# STM32U5G9xx register map
File version: 1.0
Registers are 32-bit, read-write, reset 0x0 unless marked. A register's access mark holds for its fields unless they carry their own. Offsets are from the block's base; [hi:lo] are bit positions; {n}, {i} and the like mark numbered series; 'fields as' and 'values as' point back to an identical list.

## RCC — Reset and Clock Control
Base 0x46020C00
Same registers: RCC_S 0x56020C00
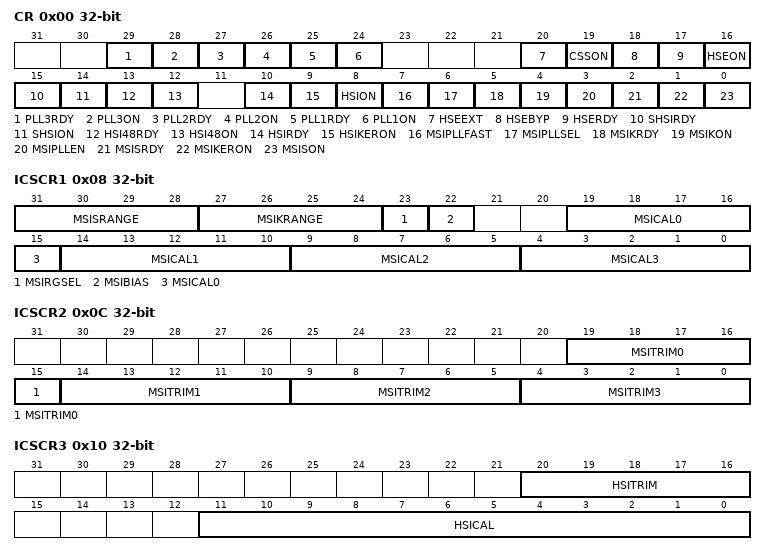
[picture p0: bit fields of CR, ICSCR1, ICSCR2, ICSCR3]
0x00 CR — RCC clock control register
  [29] PLL3RDY — System PLL 3 Ready Flag
  [28] PLL3ON — System PLL 3 Enable
  [27] PLL2RDY — System PLL 2 Ready Flag
  [26] PLL2ON — System PLL 2 Enable
  [25] PLL1RDY — System PLL 1 Clock Ready Flag
  [24] PLL1ON — System PLL 1 Clock Enable
  [20] HSEEXT — External High Speed clock type in Bypass Mode
    0=ANALOG_MODE (HSE clock used as ANALOG clock source); 1=DIGITAL_MODE (HSE clock used as DIGITAL clock source)
  [19] CSSON — HSE Clock Security System Enable
  [18] HSEBYP — External High Speed Oscillator (HSE) Clock Bypass
  [17] HSERDY — External High Speed Oscillator (HSE) Clock Ready
  [16] HSEON — External High Speed Oscillator (HSE) Clock Enable
  [15] SHSIRDY — Internal High Speed Secure (SHSI) Clock Ready Flag
  [14] SHSION — Internal High Speed Secure (SHSI) Clock Enable
  [13] HSI48RDY — Internal High Speed Oscillator (HSI48) Clock Ready Flag
  [12] HSI48ON — Internal High Speed Oscillator (HSI48) Clock Enable
  [10] HSIRDY — Internal High Speed Oscillator (HSI16) Clock Ready Flag
  [9] HSIKERON — Internal High Speed Oscillator (HSI16) Clock Enable for some IPs Kernel
  [8] HSION — Internal High Speed Oscillator (HSI16) Clock Enable
  [7] MSIPLLFAST — Internal Multi Speed Oscillator (MSI) PLL Fast Mode Selection
  [6] MSIPLLSEL — Internal Multi Speed Oscillator (MSI) PLL Mode Selection
    1=MSIS (MSIS selection for Pll Mode); 0=MSIK (MSIK selection for Pll Mode)
  [5] MSIKRDY — Internal Multi Speed Oscillator Kernel (MSIK) Ready Flag
  [4] MSIKON — Internal Multi Speed Oscillator Kernel (MSIK) Enable
  [3] MSIPLLEN — Internal Multi Speed Oscillator (MSI) PLL Mode Enable
  [2] MSISRDY — Internal Multi Speed Oscillator (MSIS) Clock Ready Flag
  [1] MSIKERON — MSI Enable for Some IPs Kernels
  [0] MSISON — Internal Multi Speed Oscillator (MSIS) Clock Enable
0x08 ICSCR1 — RCC internal clock sources calibration register 1
  [31:28] MSISRANGE — Internal Multi Speed oscillator (MSI) clock Ranges
    0=MSIS = 48 MHz; 1=MSIS = 24 MHz; 2=MSIS = 16 MHz; 3=MSIS = 12 MHz; 4=MSIS = 4 MHz; 5=MSIS = 2 MHz; 6=MSIS = 1.5 MHz; 7=MSIS = 1 MHz; 8=MSIS = 3.072 MHz; 9=MSIS = 1.536 MHz; 10=MSIS = 1.024 MHz; 11=MSIS = 768 KHz; 12=MSIS = 400 KHz; 13=MSIS = 200 KHz; 14=MSIS = 150 KHz; 15=MSISRANGE_15
  [27:24] MSIKRANGE — Internal Multi Speed oscillator Kernel (MSIK) clock Ranges
    0=MSIK = 48 MHz; 1=MSIK = 24 MHz; 2=MSIK = 16 MHz; 3=MSIK = 12 MHz; 4=MSIK = 4 MHz; 5=MSIK = 2 MHz; 6=MSIK = 1.5 MHz; 7=MSIK = 1 MHz; 8=MSIK = 3.072 MHz; 9=MSIK = 1.536 MHz; 10=MSIK = 1.024 MHz; 11=MSIK = 768 KHz; 12=MSIK = 400 KHz; 13=MSIK = 200 KHz; 14=MSIK = 150 KHz; 15=MSIKRANGE_15
  [23] MSIRGSEL — Internal Multi Speed oscillator (MSI) range selection
  [22] MSIBIAS — Internal Multi Speed oscillator (MSI) BIAS mode selection
    0=CONTINUOUS (Continuous mode selection for MSI); 1=SAMPLING (Sampling mode selection for MSI)
  [19-5n:15-5n] MSICAL{n} (n=0..3) — MSICAL[4:0] bits: MSIRC{n} Clock Calibration for MSI Ranges {4n} to {4n+3}
0x0C ICSCR2 — RCC internal clock sources calibration register 2
  [19-5n:15-5n] MSITRIM{n} (n=0..3) — MSITRIM[4:0] bits: MSI Clock Trimming for Ranges {4n} to {4n+3}
0x10 ICSCR3 — RCC internal clock sources calibration register 3
  [20:16] HSITRIM — HSITRIM[4:0] bits: HSI Clock Trimming
  [11:0] HSICAL — HSICAL[11:0] bits: HSI Clock Calibration
0x14 CRRCR — RCC Clock Recovery RC Register
  [8:0] HSI48CAL — HSI48CAL[4:0] bits: HSI48 Clock Calibration
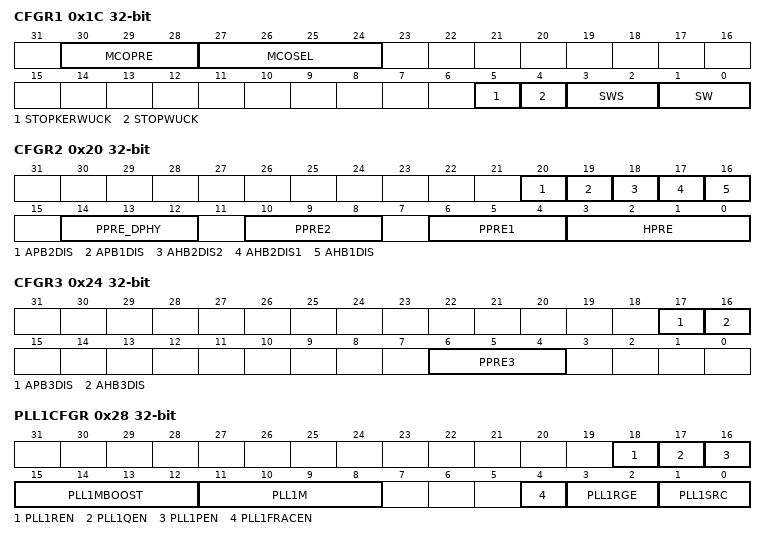
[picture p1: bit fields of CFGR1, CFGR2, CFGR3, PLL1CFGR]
0x1C CFGR1 — RCC clock configuration register 1
  [30:28] MCOPRE — MCOPRE [2:0] bits (Microcontroller Clock Output (MCO) Prescaler)
  [27:24] MCOSEL — MCOSEL [3:0] bits (Microcontroller Clock Output (MCO) Selection)
  [5] STOPKERWUCK — Kernel Clock Selection after a Wake Up from STOP
    0=MSIK (MSIK oscillator automatically enabled when exiting Stop mode); 1=HSI (HSI oscillator automatically enabled when exiting Stop mode)
  [4] STOPWUCK — Wake Up from stop and CSS backup clock selection
    0=MSIS (MSIS selection after wake-up from STOP); 1=HSI (HSI selection after wake-up from STOP)
  [3:2] SWS — SWS[1:0] bits (System Clock Switch Status)
    0=MSIS (MSIS used as system clock); 1=HSI (HSI used as system clock); 2=HSE (HSE used as system clock); 3=PLL1 (PLL1 used as system clock)
  [1:0] SW — SW[1:0] bits (System clock Switch)
    0=MSIS (MSIS selection as system clock); 1=HSI (HSI oscillator selection as system clock); 2=HSE (HSE selection as system clock); 3=PLL1 (PLL selection as system clock)
0x20 CFGR2 — RCC clock configuration register 2
  [20] APB2DIS — APB2 clock disable
  [19] APB1DIS — APB1 clock disable
  [18] AHB2DIS2 — AHB2 clock disable
  [17] AHB2DIS1 — AHB2 clock disable
  [16] AHB1DIS — AHB1 clock disable
  [14:12] PPRE_DPHY — PPRE_DPHY[2:0] bits (DPHY prescaler)
    0=DIV_1 (DCLK not divided); 4=DIV_2 (DCLK divided by 2); 5=DIV_4 (DCLK divided by 4); 6=DIV_8 (DCLK divided by 8); 7=DIV_16 (DCLK divided by 16)
  [10:8] PPRE2 — PPRE2[2:0] bits (APB2 prescaler)
    0=DIV_1 (HCLK not divided); 4=DIV_2 (HCLK divided by 2); 5=DIV_4 (HCLK divided by 4); 6=DIV_8 (HCLK divided by 8); 7=DIV_16 (HCLK divided by 16)
  [6:4] PPRE1 — PPRE1[2:0] bits (APB1 prescaler)
    values as PPRE2
  [3:0] HPRE — HPRE[3:0] bits (AHB prescaler)
    0=DIV_1 (SYSCLK not divided); 8=DIV_2 (SYSCLK divided by 2); 9=DIV_4 (SYSCLK divided by 4); 10=DIV_8 (SYSCLK divided by 8); 11=DIV_16 (SYSCLK divided by 16); 12=DIV_64 (SYSCLK divided by 64); 13=DIV_128 (SYSCLK divided by 128); 14=DIV_256 (SYSCLK divided by 256); 15=DIV_512
0x24 CFGR3 — RCC clock configuration register 3
  [17] APB3DIS — APB3 clock disable
  [16] AHB3DIS — AHB3 clock disable
  [6:4] PPRE3 — PPRE31[2:0] bits (APB3 prescaler)
    values as CFGR2.PPRE2
0x28 PLL1CFGR — PLL1 Configuration Register
  [18] PLL1REN — PLL1 DIVR Divider Output Enable
  [17] PLL1QEN — PLL1 DIVQ Divider Output Enable
  [16] PLL1PEN — PLL1 DIVP Divider Output Enable
  [15:12] PLL1MBOOST — PLL1MBOOST[3:0]: bits (Prescaler for EPOD booster input clock)
    0=DIV_1 (PLL1CLK not divided); 1=DIV_2 (PLL1CLK divided by 2); 2=DIV_4 (PLL1CLK divided by 4); 3=DIV_6 (PLL1CLK divided by 6); 4=DIV_8 (PLL1CLK divided by 8); 5=DIV_10 (PLL1CLK divided by 10); 6=DIV_12 (PLL1CLK divided by 12); 7=DIV_14; 8=DIV_16 (PLL1CLK divided by 16)
  [11:8] PLL1M — PLL1M[3:0]: bits (Prescaler for PLL1)
  [4] PLL1FRACEN — PLL1 Fractional Latch Enable
  [3:2] PLL1RGE — PLL1RGE[1:0] bits (PLL1 Input Frequency Range)
    0=PLLINPUTRANGE_4_8 (VCO input range: 4 to 8 MHz); 3=PLLINPUTRANGE_8_16 (VCO input range: 8 to 16 MHz)
  [1:0] PLL1SRC — PLL1SRC[1:0] bits (PLL1 Entry Clock Source)
    0=NONE (No clock selected as main PLL1 entry clock source); 1=MSIS (MSIS clock selected as main PLL1 entry clock source); 2=HSI (HSI clock selected as main PLL1 entry clock source); 3=HSE (HSE clock selected as main PLL1 entry clock source)
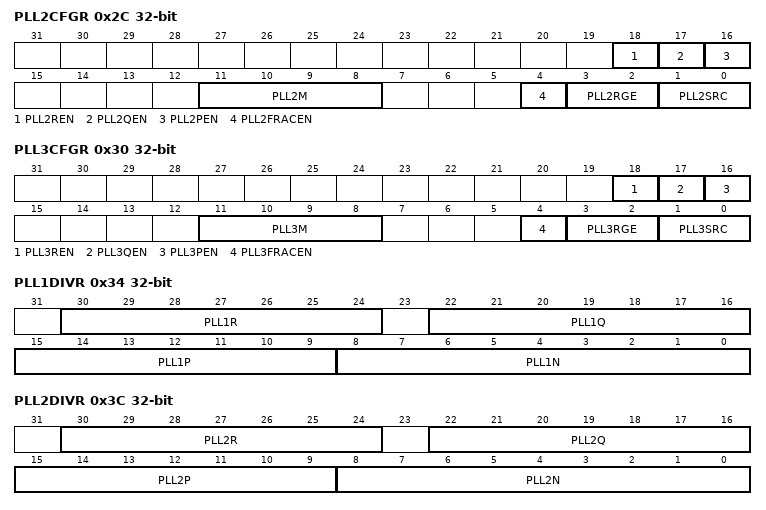
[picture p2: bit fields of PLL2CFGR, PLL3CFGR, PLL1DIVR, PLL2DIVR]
0x2C PLL2CFGR — PLL2 Configuration Register
  [18] PLL2REN — PLL2 DIVR Divider Output Enable
  [17] PLL2QEN — PLL2 DIVQ Divider Output Enable
  [16] PLL2PEN — PLL2 DIVP Divider Output Enable
  [11:8] PLL2M — PLL2M[3:0]: bits (Prescaler for PLL2)
  [4] PLL2FRACEN — PLL2 Fractional Latch Enable
  [3:2] PLL2RGE — PLL2RGE[1:0] bits (PLL2 Input Frequency Range)
    values as PLL1CFGR.PLL1RGE
  [1:0] PLL2SRC — PLL2SRC[1:0] bits (PLL2 Entry Clock Source)
    0=NONE (No clock selected as main PLL2 entry clock source); 1=MSIS (MSIS clock selected as main PLL2 entry clock source); 2=HSI (HSI clock selected as main PLL2 entry clock source); 3=HSE (HSE clock selected as main PLL2 entry clock source)
0x30 PLL3CFGR — PLL3 Configuration Register
  [18] PLL3REN — PLL3 DIVR Divider Output Enable
  [17] PLL3QEN — PLL3 DIVQ Divider Output Enable
  [16] PLL3PEN — PLL3 DIVP Divider Output Enable
  [11:8] PLL3M — PLL3M[3:0]: bits (Prescaler for PLL3)
  [4] PLL3FRACEN — PLL3 Fractional Latch Enable
  [3:2] PLL3RGE — PLL3RGE[1:0] bits (PLL3 Input Frequency Range)
    values as PLL1CFGR.PLL1RGE
  [1:0] PLL3SRC — PLL3SRC[1:0] bits (PLL3 Entry Clock Source)
    0=NONE (No clock selected as main PLL3 entry clock source); 1=MSIS (MSIS clock selected as main PLL3 entry clock source); 2=HSI (HSI clock selected as main PLL3 entry clock source); 3=HSE (HSE clock selected as main PLL3 entry clock source)
0x34 PLL1DIVR — PLL1 Dividers Configuration Register
  [30:24] PLL1R — PLL1R[6:0]: bits (PLL1 DIVR Division Factor)
  [22:16] PLL1Q — PLL1Q[6:0]: bits (PLL1 DIVQ Division Factor)
  [15:9] PLL1P — PLL1P[6:0]: bits (PLL1 DIVP Division Factor)
  [8:0] PLL1N — PLL1N[8:0]: bits (Multiplication Factor For PLL1 VCO)
{0x30+8i} PLL{i}FRACR (i=1..3) — PLL{i} Fractional Divider Configuration Register
  [15:3] PLL{i}FRACN — PLL{i}FRACN[12:0]: bits (Fractional Part of the Multiplication Factor for PLL{i} VCO)
0x3C PLL2DIVR — PLL2 Dividers Configuration Register
  [30:24] PLL2R — PLL2R[6:0]: bits (PLL2 DIVR Division Factor)
  [22:16] PLL2Q — PLL2Q[6:0]: bits (PLL2 DIVQ Division Factor)
  [15:9] PLL2P — PLL2P[6:0]: bits (PLL2 DIVP Division Factor)
  [8:0] PLL2N — PLL2N[8:0]: bits (Multiplication Factor for PLL2 VCO)
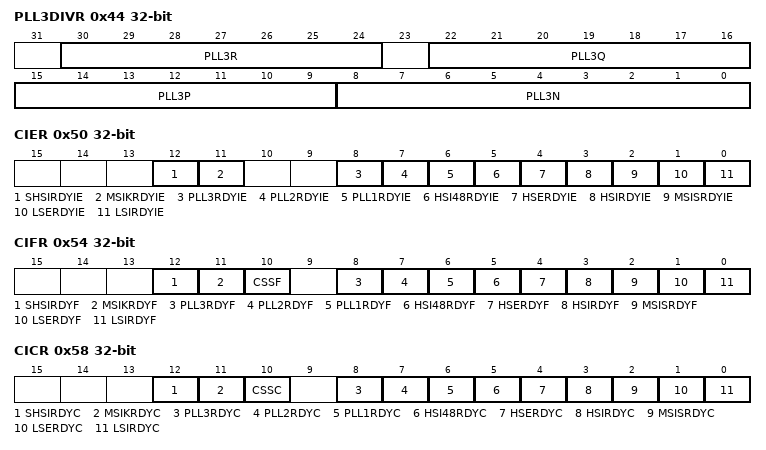
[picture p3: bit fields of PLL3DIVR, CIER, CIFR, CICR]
0x44 PLL3DIVR — PLL3 Dividers Configuration Register
  [30:24] PLL3R — PLL3R[6:0]: bits (PLL3 DIVR Division Factor)
  [22:16] PLL3Q — PLL3Q[6:0]: bits (PLL3 DIVQ Division Factor)
  [15:9] PLL3P — PLL3P[6:0]: bits (PLL2 DIVP Division Factor)
  [8:0] PLL3N — PLL3N[8:0]: bits (Multiplication Factor for PLL3 VCO)
0x50 CIER — Clock Interrupt Enable Register
  [12] SHSIRDYIE — SHSI Ready Interrupt Enable
  [11] MSIKRDYIE — MSIK Ready Interrupt Enable
  [8] PLL3RDYIE — PLL3 Ready Interrupt Enable
  [7] PLL2RDYIE — PLL2 Ready Interrupt Enable
  [6] PLL1RDYIE — PLL Ready Interrupt Enable
  [5] HSI48RDYIE — HSI48 Ready Interrupt Enable
  [4] HSERDYIE — HSE Ready Interrupt Enable
  [3] HSIRDYIE — HSI16 Ready Interrupt Enable
  [2] MSISRDYIE — MSIS Ready Interrupt Enable
  [1] LSERDYIE — LSE Ready Interrupt Enable
  [0] LSIRDYIE — LSI Ready Interrupt Enable
0x54 CIFR — Clock Interrupt Flag Register
  [12] SHSIRDYF — SHSI Ready Interrupt Flag
  [11] MSIKRDYF — MSIK Ready Interrupt Flag
  [10] CSSF — Clock Security System Interrupt Flag
  [8] PLL3RDYF — PLL3 Ready Interrupt Flag
  [7] PLL2RDYF — PLL2 Ready Interrupt Flag
  [6] PLL1RDYF — PLL1 Ready Interrupt Flag
  [5] HSI48RDYF — HSI48 Ready Interrupt Flag
  [4] HSERDYF — HSE Ready Interrupt Flag
  [3] HSIRDYF — HSI16 Ready Interrupt Flag
  [2] MSISRDYF — MSIS Ready Interrupt Flag
  [1] LSERDYF — LSE Ready Interrupt Flag
  [0] LSIRDYF — LSI Ready Interrupt Flag
0x58 CICR — Clock Interrupt Clear Register
  [12] SHSIRDYC — SHSI Ready Interrupt Clear
  [11] MSIKRDYC — MSIK Ready Interrupt Clear
  [10] CSSC — Clock Security System Interrupt Clear
  [8] PLL3RDYC — PLL3 Ready Interrupt Clear
  [7] PLL2RDYC — PLL2 Ready Interrupt Clear
  [6] PLL1RDYC — PLL1 Ready Interrupt Clear
  [5] HSI48RDYC — HSI48 Ready Interrupt Clear
  [4] HSERDYC — HSE Ready Interrupt Clear
  [3] HSIRDYC — HSI16 Ready Interrupt Clear
  [2] MSISRDYC — MSIS Ready Interrupt Clear
  [1] LSERDYC — LSE Ready Interrupt Clear
  [0] LSIRDYC — LSI Ready Interrupt Clear
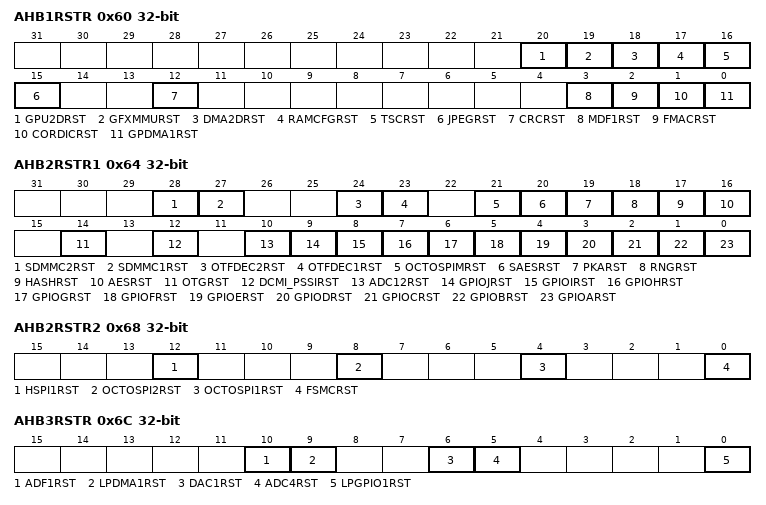
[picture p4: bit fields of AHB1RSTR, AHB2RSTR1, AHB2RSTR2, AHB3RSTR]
0x60 AHB1RSTR — AHB1 Peripherals Reset Register
  [20] GPU2DRST
  [19] GFXMMURST
  [18] DMA2DRST — DMA2D Reset
  [17] RAMCFGRST — RAMCFG Reset
  [16] TSCRST — TSC Reset
  [15] JPEGRST — JPEG Reset
  [12] CRCRST — CRC Reset
  [3] MDF1RST — MDF1 Reset
  [2] FMACRST — FMAC Reset
  [1] CORDICRST — CORDIC Reset
  [0] GPDMA1RST — GPDMA1 Reset
0x64 AHB2RSTR1 — AHB2 Peripherals Reset Register 1
  [28] SDMMC2RST — SDMMC2 Reset
  [27] SDMMC1RST — SDMMC1 Reset
  [24] OTFDEC2RST — OTFDEC2 Reset
  [23] OTFDEC1RST — OTFDEC1 Reset
  [21] OCTOSPIMRST — OCTOSPIM Reset
  [20] SAESRST — SAES Hardware Accelerator Reset
  [19] PKARST — PKA reset
  [18] RNGRST — Random Number Generator Reset
  [17] HASHRST — Hash Reset
  [16] AESRST — AES Hardware Accelerator Reset
  [14] OTGRST — OTG Reset
  [12] DCMI_PSSIRST — DCMI and PSSI Reset
  [10] ADC12RST — ADC1 Reset
  [9] GPIOJRST
  [8] GPIOIRST — IO port I Reset
  [7] GPIOHRST — IO port H Reset
  [6] GPIOGRST — IO port G Reset
  [5] GPIOFRST — IO port F Reset
  [4] GPIOERST — IO port E Reset
  [3] GPIODRST — IO port D Reset
  [2] GPIOCRST — IO port C Reset
  [1] GPIOBRST — IO port B Reset
  [0] GPIOARST — IO port A Reset
0x68 AHB2RSTR2 — AHB2 Peripherals Reset Register 2
  [12] HSPI1RST
  [8] OCTOSPI2RST — OCTOSPI2 Reset
  [4] OCTOSPI1RST — OCTOSPI1 Reset
  [0] FSMCRST — Flexible Memory Controller Reset
0x6C AHB3RSTR — AHB3 Peripherals Reset Register
  [10] ADF1RST — ADF1 Reset
  [9] LPDMA1RST — LPDMA1 Reset
  [6] DAC1RST — DAC1 Reset
  [5] ADC4RST — ADC4 Reset
  [0] LPGPIO1RST — LPGPIO1 Reset
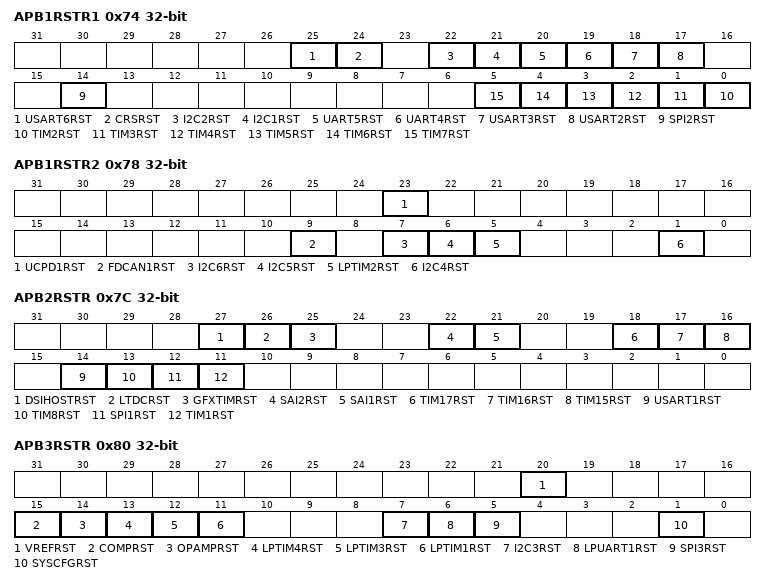
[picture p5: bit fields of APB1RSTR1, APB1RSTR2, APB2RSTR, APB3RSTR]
0x74 APB1RSTR1 — APB1 Peripherals Reset Register 1
  [25] USART6RST
  [24] CRSRST — CRS Reset
  [22] I2C2RST — I2C2 Reset
  [21] I2C1RST — I2C1 Reset
  [20] UART5RST — UART5 Reset
  [19] UART4RST — UART4 Reset
  [18] USART3RST — USART3 Reset
  [17] USART2RST — USART2 Reset
  [14] SPI2RST — SPI2 Reset
  [n-2] TIM{n}RST (n=2..7) — TIM{n} Reset
0x78 APB1RSTR2 — APB1 Peripherals Reset Register 2
  [23] UCPD1RST — UCPD1 Reset
  [9] FDCAN1RST — FDCAN1 Reset
  [7] I2C6RST
  [6] I2C5RST
  [5] LPTIM2RST — LPTIM2 Reset
  [1] I2C4RST — I2C4 Reset
0x7C APB2RSTR — APB2 Peripherals Reset Register
  [27] DSIHOSTRST
  [26] LTDCRST
  [25] GFXTIMRST — GFXTIM Reset
  [22] SAI2RST — SAI2 Reset
  [21] SAI1RST — SAI1 Reset
  [18] TIM17RST — TIM17 Reset
  [17] TIM16RST — TIM16 Reset
  [16] TIM15RST — TIM15 Reset
  [14] USART1RST — USART1 Reset
  [13] TIM8RST — TIM8 Reset
  [12] SPI1RST — SPI1 Reset
  [11] TIM1RST — TIM1 Reset
0x80 APB3RSTR — APB3 Peripherals Reset Register
  [20] VREFRST — VREFBUF Reset
  [15] COMPRST — COMP Reset
  [14] OPAMPRST — OPAMP Reset
  [13] LPTIM4RST — LPTIM4 Reset
  [12] LPTIM3RST — LPTIM3 Reset
  [11] LPTIM1RST — LPTIM1 Reset
  [7] I2C3RST — I2C3 Reset
  [6] LPUART1RST — LPUART1 Reset
  [5] SPI3RST — SPI3 Reset
  [1] SYSCFGRST — SYSCFG Reset
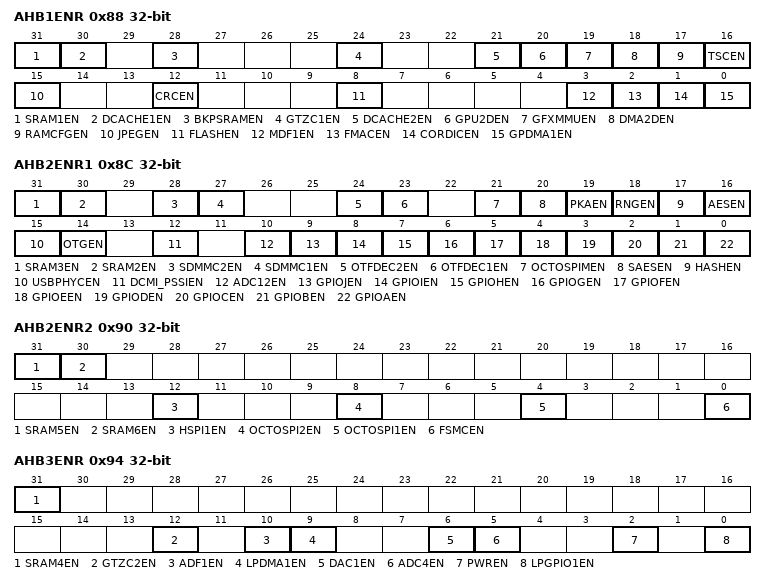
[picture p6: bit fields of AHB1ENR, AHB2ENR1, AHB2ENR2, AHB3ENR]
0x88 AHB1ENR — AHB1 Peripherals Clock Enable Register
  [31] SRAM1EN — SRAM1 Clock Enable
  [30] DCACHE1EN — DCACHE1 Clock Enable
  [28] BKPSRAMEN — BKPSRAM Clock Enable
  [24] GTZC1EN — GTZC1 Clock Enable
  [21] DCACHE2EN — DCACHE2 Clock Enable
  [20] GPU2DEN — GPU2D Clock Enable
  [19] GFXMMUEN — GFXMMU Clock Enable
  [18] DMA2DEN — DMA2D Clock Enable
  [17] RAMCFGEN — RAMCFG Clock Enable
  [16] TSCEN — Touch Sensing Controller Clock Enable
  [15] JPEGEN — JPEG Clock Enable
  [12] CRCEN — CRC Clock Enable
  [8] FLASHEN — FLASH Clock Enable
  [3] MDF1EN — MDF1 Clock Enable
  [2] FMACEN — FMAC Clock Enable
  [1] CORDICEN — CORDIC Clock Enable
  [0] GPDMA1EN — GPDMA1 Clock Enable
0x8C AHB2ENR1 — AHB2 Peripherals Clock Enable Register 1
  [31] SRAM3EN — SRAM3 Clock Enable
  [30] SRAM2EN — SRAM2 Clock Enable
  [28] SDMMC2EN — SDMMC2 Clock Enable
  [27] SDMMC1EN — SDMMC1 Clock Enable
  [24] OTFDEC2EN — OTFDEC2 Clock Enable
  [23] OTFDEC1EN — OTFDEC1 Clock Enable
  [21] OCTOSPIMEN — OCTOSPIM Clock Enable
  [20] SAESEN — SAES Clock Enable
  [19] PKAEN — PKA Clock Enable
  [18] RNGEN — RNG Clock Enable
  [17] HASHEN — HASH Clock Enable
  [16] AESEN — AES Clock Enable
  [15] USBPHYCEN
  [14] OTGEN — OTG Clock Enable
  [12] DCMI_PSSIEN — DCMI and PSSI Clock Enable
  [10] ADC12EN — ADC1 Clock Enable
  [9] GPIOJEN — GPIOJ Clock Enable
  [8] GPIOIEN — IO port I Clock Enable
  [7] GPIOHEN — IO port H Clock Enable
  [6] GPIOGEN — IO port G Clock Enable
  [5] GPIOFEN — IO port F Clock Enable
  [4] GPIOEEN — IO port E Clock Enable
  [3] GPIODEN — IO port D Clock Enable
  [2] GPIOCEN — IO port C Clock Enable
  [1] GPIOBEN — IO port B Clock Enable
  [0] GPIOAEN — IO port A Clock Enable
0x90 AHB2ENR2 — AHB2 Peripherals Clock Enable Register 2
  [31] SRAM5EN — SRAM5 Clock Enable
  [30] SRAM6EN — SRAM6 Clock Enable
  [12] HSPI1EN — HSPI1 Clock Enable
  [8] OCTOSPI2EN — OCTOSPI2 Clock Enable
  [4] OCTOSPI1EN — OCTOSPI1 Clock Enable
  [0] FSMCEN — FSMC Clock Enable
0x94 AHB3ENR — AHB3 Peripherals Clock Enable Register
  [31] SRAM4EN — SRAM4 Clock Enable
  [12] GTZC2EN — GTZC2 Clock Enable
  [10] ADF1EN — ADF1 Clock Enable
  [9] LPDMA1EN — LPDMA1 Clock Enable
  [6] DAC1EN — DAC1 Clock Enable
  [5] ADC4EN — ADC4 Clock Enable
  [2] PWREN — PWR Clock Enable
  [0] LPGPIO1EN — LPGPIO1 Enable
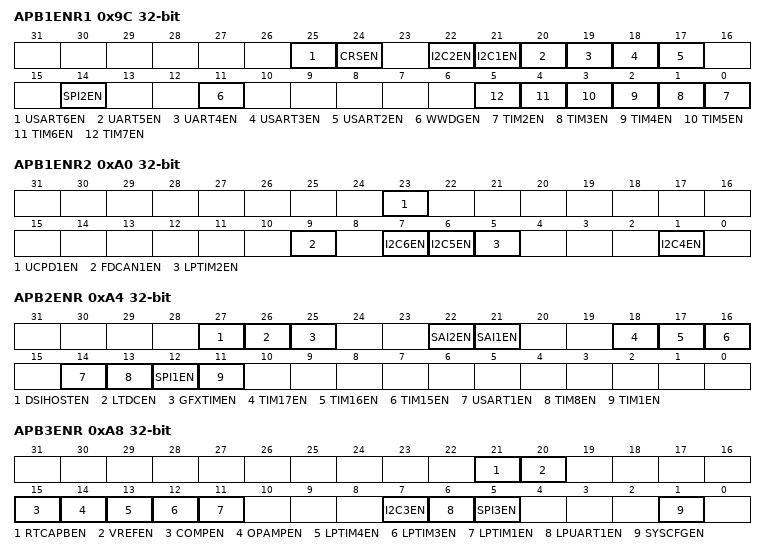
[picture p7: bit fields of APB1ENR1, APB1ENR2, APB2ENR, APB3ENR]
0x9C APB1ENR1 — APB1 Peripherals Clock Enable Register 1
  [25] USART6EN — USART6 Clock Enable
  [24] CRSEN — CRS Clock Enable
  [22] I2C2EN — I2C2 Clock Enable
  [21] I2C1EN — I2C1 Clock Enable
  [20] UART5EN — UART5 Clock Enable
  [19] UART4EN — UART4 Clock Enable
  [18] USART3EN — USART3 Clock Enable
  [17] USART2EN — USART2 Clock Enable
  [14] SPI2EN — SPI2 Clock Enable
  [11] WWDGEN — WWDG Clock Enable
  [n-2] TIM{n}EN (n=2..7) — TIM{n} Clock Enable
0xA0 APB1ENR2 — APB1 Peripherals Clock Enable Register 2
  [23] UCPD1EN — UCPD1 Clock Enable
  [9] FDCAN1EN — FDCAN1 Clock Enable
  [7] I2C6EN — I2C6 Clock Enable
  [6] I2C5EN — I2C5 Clock Enable
  [5] LPTIM2EN — LPTIM2 Clock Enable
  [1] I2C4EN — I2C4 Clock Enable
0xA4 APB2ENR — APB2 Peripherals Clock Enable Register
  [27] DSIHOSTEN — DSI Clock Enable
  [26] LTDCEN — LTDC Clock Enable
  [25] GFXTIMEN — GFXTIM Clock Enable
  [22] SAI2EN — SAI2 Clock Enable
  [21] SAI1EN — SAI1 Clock Enable
  [18] TIM17EN — TIM17 Clock Enable
  [17] TIM16EN — TIM16 Clock Enable
  [16] TIM15EN — TIM15 Clock Enable
  [14] USART1EN — USART1 Clock Enable
  [13] TIM8EN — TIM8 Clock Enable
  [12] SPI1EN — SPI1 Clock Enable
  [11] TIM1EN — TIM1 Clock Enable
0xA8 APB3ENR — APB3 Peripherals Clock Enable Register
  [21] RTCAPBEN — RTC APB Clock Enable
  [20] VREFEN — VREFBUF Clock Enable
  [15] COMPEN — COMP Clock Enable
  [14] OPAMPEN — OPAMP Clock Enable
  [13] LPTIM4EN — LPTIM4 Clock Enable
  [12] LPTIM3EN — LPTIM3 Clock Enable
  [11] LPTIM1EN — LPTIM1 Clock Enable
  [7] I2C3EN — I2C3 Clock Enable
  [6] LPUART1EN — LPUART1 Clock Enable
  [5] SPI3EN — SPI3 Clock Enable
  [1] SYSCFGEN — SYSCFG Clock Enable
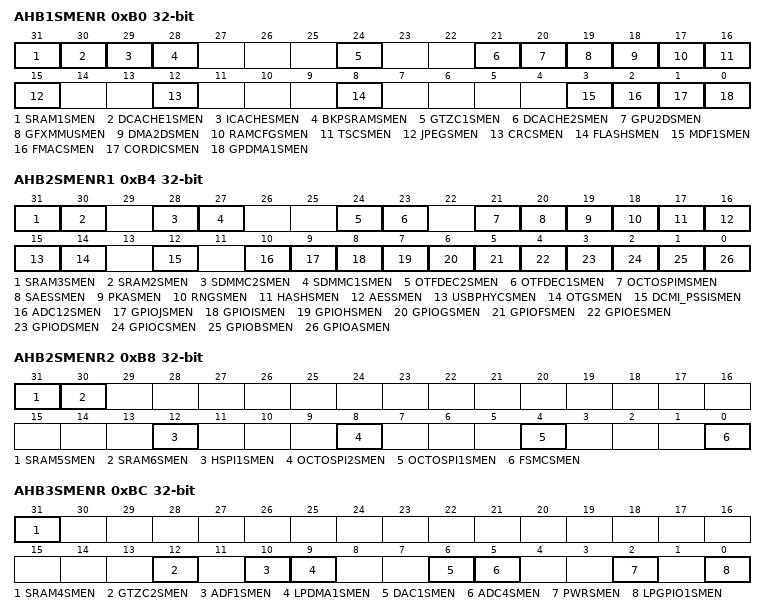
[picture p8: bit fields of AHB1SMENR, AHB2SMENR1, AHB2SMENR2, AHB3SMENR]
0xB0 AHB1SMENR — AHB1 Peripherals Clock Enable in Sleep and Stop Modes Register
  [31] SRAM1SMEN — SRAM1 Clocks Enable During Sleep and Stop Modes
  [30] DCACHE1SMEN — DCACHE1 Clocks Enable During Sleep and Stop Modes
  [29] ICACHESMEN — ICACHE Clocks Enable During Sleep and Stop Modes
  [28] BKPSRAMSMEN — BKPSRAM Clocks Enable During Sleep and Stop Modes
  [24] GTZC1SMEN — GTZC1 Clocks Enable During Sleep and Stop Modes
  [21] DCACHE2SMEN — DCACHE2 Clocks Enable During Sleep and Stop Modes
  [20] GPU2DSMEN — GPU2D Clocks Enable During Sleep and Stop Modes
  [19] GFXMMUSMEN — GFXMMU Clocks Enable During Sleep and Stop Modes
  [18] DMA2DSMEN — DMA2D Clocks Enable During Sleep and Stop Modes
  [17] RAMCFGSMEN — RAMCFG Clocks Enable During Sleep and Stop Modes
  [16] TSCSMEN — TSC Clocks Enable During Sleep and Stop Modes
  [15] JPEGSMEN — JPEG Clocks Enable During Sleep and Stop Modes
  [12] CRCSMEN — CRC Clocks Enable During Sleep and Stop Modes
  [8] FLASHSMEN — FLASH Clocks Enable During Sleep and Stop Modes
  [3] MDF1SMEN — MDF1 Clocks Enable During Sleep and Stop Modes
  [2] FMACSMEN — FMAC Clocks Enable During Sleep and Stop Modes
  [1] CORDICSMEN — CORDIC Clocks Enable During Sleep and Stop Modes
  [0] GPDMA1SMEN — GPDMA1 Clocks Enable During Sleep and Stop Modes
0xB4 AHB2SMENR1 — AHB2 Peripherals Clock Enable in Sleep and Stop Modes Register 1
  [31] SRAM3SMEN — SRAM3 Clocks Enable During Sleep and Stop Modes
  [30] SRAM2SMEN — SRAM2 Clocks Enable During Sleep and Stop Modes
  [28] SDMMC2SMEN — SDMMC2 Clocks Enable During Sleep and Stop Modes
  [27] SDMMC1SMEN — SDMMC1 Clocks Enable During Sleep and Stop Modes
  [24] OTFDEC2SMEN — OTFDEC2 Clocks Enable During Sleep and Stop Modes
  [23] OTFDEC1SMEN — OTFDEC1 Clocks Enable During Sleep and Stop Modes
  [21] OCTOSPIMSMEN — OCTOSPIM Clocks Enable During Sleep and Stop Modes
  [20] SAESSMEN — SAES Clocks Enable During Sleep and Stop Modes
  [19] PKASMEN — PKA Clocks Enable During Sleep and Stop Modes
  [18] RNGSMEN — Random Number Generator (RNG) Clocks Enable During Sleep and Stop Modes
  [17] HASHSMEN — HASH Clocks Enable During Sleep and Stop Modes
  [16] AESSMEN — AES Clocks Enable During Sleep and Stop Modes
  [15] USBPHYCSMEN
  [14] OTGSMEN — OTG Clocks Enable During Sleep and Stop Modes
  [12] DCMI_PSSISMEN — DCMI and PSSI Clocks Enable During Sleep and Stop Modes
  [10] ADC12SMEN — ADC1 Clocks Enable During Sleep and Stop Modes
  [9] GPIOJSMEN — IO port J Clocks Enable During Sleep and Stop Modes
  [8] GPIOISMEN — IO port I Clocks Enable During Sleep and Stop Modes
  [7] GPIOHSMEN — IO port H Clocks Enable During Sleep and Stop Modes
  [6] GPIOGSMEN — IO port G Clocks Enable During Sleep and Stop Modes
  [5] GPIOFSMEN — IO port F Clocks Enable During Sleep and Stop Modes
  [4] GPIOESMEN — IO port E Clocks Enable During Sleep and Stop Modes
  [3] GPIODSMEN — IO port D Clocks Enable During Sleep and Stop Modes
  [2] GPIOCSMEN — IO port C Clocks Enable During Sleep and Stop Modes
  [1] GPIOBSMEN — IO port B Clocks Enable During Sleep and Stop Modes
  [0] GPIOASMEN — IO port A Clocks Enable During Sleep and Stop Modes
0xB8 AHB2SMENR2 — AHB2 Peripherals Clock Enable in Sleep and Stop Modes Register 2
  [31] SRAM5SMEN — SRAM5 Clocks Enable During Sleep and Stop Modes
  [30] SRAM6SMEN — SRAM6 Clocks Enable During Sleep and Stop Modes
  [12] HSPI1SMEN — HSPI1 Clocks Enable During Sleep and Stop Modes
  [8] OCTOSPI2SMEN — OCTOSPI2 Clocks Enable During Sleep and Stop Modes
  [4] OCTOSPI1SMEN — OCTOSPI1 Clocks Enable During Sleep and Stop Modes
  [0] FSMCSMEN — FSMC Clocks Enable During Sleep and Stop Modes
0xBC AHB3SMENR — AHB3 Peripherals Clock Enable in Sleep and Stop Modes Register
  [31] SRAM4SMEN — SRAM4 Clocks Enable During Sleep and Stop Modes
  [12] GTZC2SMEN — GTZC2 Clocks Enable During Sleep and Stop Modes
  [10] ADF1SMEN — ADF1 Clocks Enable During Sleep and Stop Modes
  [9] LPDMA1SMEN — LPDMA1 Clocks Enable During Sleep and Stop Modes
  [6] DAC1SMEN — DAC1 Clocks Enable During Sleep and Stop Modes
  [5] ADC4SMEN — ADC4 Clocks Enable During Sleep and Stop Modes
  [2] PWRSMEN — PWR Clocks Enable During Sleep and Stop Modes
  [0] LPGPIO1SMEN — LPGPIO1 Clocks Enable During Sleep and Stop Modes
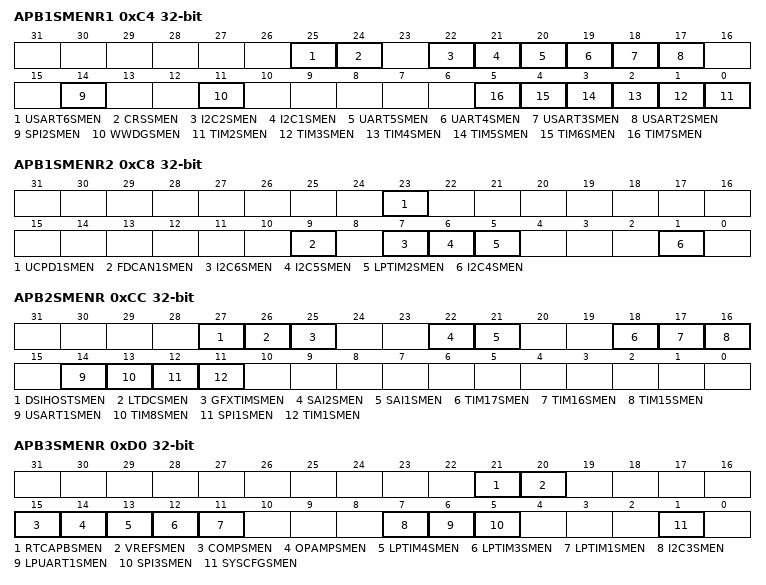
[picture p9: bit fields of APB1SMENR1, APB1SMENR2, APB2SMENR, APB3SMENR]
0xC4 APB1SMENR1 — APB1 Peripherals Clock Enable in Sleep and Stop Modes Register 1
  [25] USART6SMEN
  [24] CRSSMEN — CRS Clocks Enable During Sleep and Stop Modes
  [22] I2C2SMEN — I2C2 Clocks Enable During Sleep and Stop Modes
  [21] I2C1SMEN — I2C1 Clocks Enable During Sleep and Stop Modes
  [20] UART5SMEN — UART5 Clocks Enable During Sleep and Stop Modes
  [19] UART4SMEN — UART4 Clocks Enable During Sleep and Stop Modes
  [18] USART3SMEN — USART3 Clocks Enable During Sleep and Stop Modes
  [17] USART2SMEN — USART2 Clocks Enable During Sleep and Stop Modes
  [14] SPI2SMEN — SPI2 Clocks Enable During Sleep and Stop Modes
  [11] WWDGSMEN — Window Watchdog Clocks Enable During Sleep and Stop Modes
  [n-2] TIM{n}SMEN (n=2..7) — TIM{n} Clocks Enable During Sleep and Stop Modes
0xC8 APB1SMENR2 — APB1 Peripherals Clock Enable in Sleep and Stop Modes Register 2
  [23] UCPD1SMEN — UCPD1 Clocks Enable During Sleep and Stop Modes
  [9] FDCAN1SMEN — FDCAN1 Clocks Enable During Sleep and Stop Modes
  [7] I2C6SMEN — I2C6 Clocks Enable During Sleep and Stop Modes
  [6] I2C5SMEN — I2C5 Clocks Enable During Sleep and Stop Modes
  [5] LPTIM2SMEN — LPTIM2 Clocks Enable During Sleep and Stop Modes
  [1] I2C4SMEN — I2C4 Clocks Enable During Sleep and Stop Modes
0xCC APB2SMENR — APB2 Peripherals Clock Enable in Sleep and Stop Modes Register 1
  [27] DSIHOSTSMEN — SAI2 Clocks Enable During Sleep and Stop Modes
  [26] LTDCSMEN — SAI2 Clocks Enable During Sleep and Stop Modes
  [25] GFXTIMSMEN — GFXTIM Clocks Enable During Sleep and Stop Modes
  [22] SAI2SMEN — SAI2 Clocks Enable During Sleep and Stop Modes
  [21] SAI1SMEN — SAI1 Clocks Enable During Sleep and Stop Modes
  [18] TIM17SMEN — TIM17 Clocks Enable During Sleep and Stop Modes
  [17] TIM16SMEN — TIM16 Clocks Enable During Sleep and Stop Modes
  [16] TIM15SMEN — TIM15 Clocks Enable During Sleep and Stop Modes
  [14] USART1SMEN — USART1 Clocks Enable During Sleep and Stop Modes
  [13] TIM8SMEN — TIM8 Clocks Enable During Sleep and Stop Modes
  [12] SPI1SMEN — SPI1 Clocks Enable During Sleep and Stop Modes
  [11] TIM1SMEN — TIM1 Clocks Enable During Sleep and Stop Modes
0xD0 APB3SMENR — APB3 Peripherals Clock Enable in Sleep and Stop Modes Register 2
  [21] RTCAPBSMEN — RTC APB Clocks Enable During Sleep and Stop Modes
  [20] VREFSMEN — VREFBUF Clocks Enable During Sleep and Stop Modes
  [15] COMPSMEN — COMP Clocks Enable During Sleep and Stop Modes
  [14] OPAMPSMEN — OPAMP Clocks Enable During Sleep and Stop Modes
  [13] LPTIM4SMEN — LPTIM4 Clocks Enable During Sleep and Stop Modes
  [12] LPTIM3SMEN — LPTIM3 Clocks Enable During Sleep and Stop Modes
  [11] LPTIM1SMEN — LPTIM1 Clocks Enable During Sleep and Stop Modes
  [7] I2C3SMEN — I2C3 Clocks Enable During Sleep and Stop Modes
  [6] LPUART1SMEN — LPUART1 Clocks Enable During Sleep and Stop Modes
  [5] SPI3SMEN — SPI3 Clocks Enable During Sleep and Stop Modes
  [1] SYSCFGSMEN — SYSCFG Clocks Enable During Sleep and Stop Modes
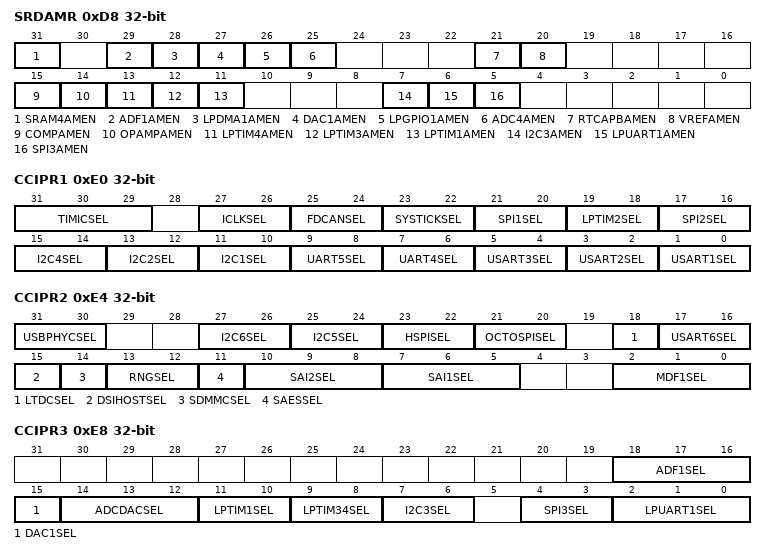
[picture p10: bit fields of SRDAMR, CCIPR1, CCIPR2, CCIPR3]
0xD8 SRDAMR — SRD Autonomous Mode Register
  [31] SRAM4AMEN — SRAM4 Autonomous Mode Enable in Stop 0,1,2 Mode
  [29] ADF1AMEN — ADF1 Autonomous Mode Enable in Stop 0,1,2 Mode
  [28] LPDMA1AMEN — LPDMA1 Autonomous Mode Enable in Stop 0,1,2 Mode
  [27] DAC1AMEN — DAC1 Autonomous Mode Enable in Stop 0,1,2 Mode
  [26] LPGPIO1AMEN — LPGPIO1 Autonomous Mode Enable in Stop 0,1,2 Mode
  [25] ADC4AMEN — ADC4 Autonomous Mode Enable in Stop 0,1,2 Mode
  [21] RTCAPBAMEN — RTC Autonomous Mode Enable in Stop 0,1,2 Mode
  [20] VREFAMEN — VREFBUF Autonomous Mode Enable in Stop 0,1,2 Mode
  [15] COMPAMEN — COMP Autonomous Mode Enable in Stop 0,1,2 Mode
  [14] OPAMPAMEN — OPAMP Autonomous Mode Enable in Stop 0,1,2 Mode
  [13] LPTIM4AMEN — LPTIM4 Autonomous Mode Enable in Stop 0,1,2 Mode
  [12] LPTIM3AMEN — LPTIM3 Autonomous Mode Enable in Stop 0,1,2 Mode
  [11] LPTIM1AMEN — LPTIM1 Autonomous Mode Enable in Stop 0,1,2 Mode
  [7] I2C3AMEN — I2C3 Autonomous Mode Enable in Stop 0,1,2 Mode
  [6] LPUART1AMEN — LPUART1 Autonomous Mode Enable in Stop 0,1,2 Mode
  [5] SPI3AMEN — SPI3 Autonomous Mode Enable in Stop 0,1,2 Mode
0xE0 CCIPR1 — IPs Clocks Configuration Register 1
  [31:29] TIMICSEL — TIMICSEL[2:0]: bits (Clocks Sources for TIM16,TIM17 and LPTIM2 Internal Input Capture)
    0=NONE (No clock available for TIM16/TIM17 and LPTIM2 input capture); 4=HSI_DIV256 (HSI/256 selected for TIM16/TIM17 and LPTIM2 input capture); 6=MSIS_DIV4 (MSIS/4 selected for TIM16/TIM17 and LPTIM2 input capture); 5=MSIK_DIV4 (MSIK/4 selected for TIM16/TIM17 and LPTIM2 input capture); 7=MSIK_DIV1024
  [27:26] ICLKSEL — ICLKSEL[1:0]: bits (48 MHz Clock Source Selection)
    0=HSI48 (HSI48 clock used as SDMMC1/2 clock source); 2=PLL1 (PLL1 "Q" clock used as SDMMC1/2 clock source); 1=PLL2 (PLL2 "Q" clock used as SDMMC1/2 clock source); 3=MSIK (MSIK clock used as SDMMC1/2 clock source)
  [25:24] FDCANSEL — FDCAN1SEL[1:0]: bits (FDCAN1 Kernel Clock Source Selection)
    0=HSE (HSE clock used as FDCAN kernel clock source); 1=PLL1 (PLL1 Q clock used as FDCAN kernel clock source); 2=PLL2 (PLL2 P clock used as FDCAN kernel clock source)
  [23:22] SYSTICKSEL — SYSTICKSEL[1:0]: bits (SYSTICK Clock Source Selection)
    1=LSI (LSI clock used as SYSTICK clock source); 2=LSE (LSE clock used as SYSTICK clock source); 0=HCLKDIV8 (HCLKDIV8 clock used as SYSTICK clock source)
  [21:20] SPI1SEL — SPI1SEL[1:0]: bits (SPI1 Kernel Clock Source Selection)
  [19:18] LPTIM2SEL — LPTIM2SEL[1:0]: bits (Low-power Timer 2 Kernel Clock Source Selection)
  [17:16] SPI2SEL — SPI2SEL[1:0]: bits (SPI2 Kernel Clock Source Selection)
  [15:14] I2C4SEL — I2C4SEL[1:0]: bits (I2C4 Kernel Clock Source Selection)
  [13:12] I2C2SEL — I2C2SEL[1:0]: bits (I2C2 Kernel Clock Source Selection)
  [11:10] I2C1SEL — I2C1SEL[1:0]: bits (I2C1 Kernel Clock Source Selection)
  [9:8] UART5SEL — UART5SEL[1:0]: bits (UART5 Kernel Clock Source Selection)
  [7:6] UART4SEL — UART4SEL[1:0]: bits (UART4 Kernel Clock Source Selection)
  [5:4] USART3SEL — USART3SEL[1:0]: bits (USART3 Kernel Clock Source Selection)
  [3:2] USART2SEL — USART2SEL[1:0]: bits (USART2 Kernel Clock Source Selection)
  [1:0] USART1SEL — USART1SEL[1:0]: bits (USART1 Kernel Clock Source Selection)
0xE4 CCIPR2 — IPs Clocks Configuration Register 2
  [31:30] USBPHYCSEL — OTG Kernel Clock Source Selection
    0=HSE (HSE clock selected as USBPHYC clock); 2=HSE_DIV2 (HSE clock divided by 2 selected as USBPHYC clock); 1=PLL1 (PLL1 divider P selected as USBPHYC clock); 3=PLL1_DIV2 (PLL1 divider P divided by 2 selected as USBPHYC clock)
  [27:26] I2C6SEL — I2C6 Kernel Clock Source Selection
  [25:24] I2C5SEL — I2C5 Kernel Clock Source Selection
  [23:22] HSPISEL — HSPI1 Kernel Clock Source Selection
    0=SYSCLK; 1=PLL1; 2=PLL2; 3=PLL3
  [21:20] OCTOSPISEL — OCTOSPISEL[1:0]: bits (OCTOSPI1 and OCTOSPI2 Kernel Clock Source Selection)
    0=SYSCLK (SYSCLK clock used as OctoSPI kernel clock source); 1=MSIK (MSIK clock used as OctoSPI kernel clock source); 2=PLL1 (PLL1 "Q" clock used as OctoSPI kernel clock source); 3=PLL2 (PLL2 "Q" clock used as OctoSPI kernel clock source)
  [18] LTDCSEL — LTDC Kernel Clock Source Selection
    1=PLL2; 0=PLL3
  [17:16] USART6SEL — USART6 Kernel Clock Source Selection
  [15] DSIHOSTSEL — DSI Kernel Clock Source Selection
    1=PHY; 0=PLL3
  [14] SDMMCSEL — SDMMC1 Kernel Clock Source Selection
    0=KERNELCLKSOURCE_48CLK (48MHz clock from internal multiplexor used as SDMMC1/2 clock source); 1=PLL1 (PLL1 "P" used as SDMMC1/2 clock source)
  [13:12] RNGSEL — RNGSEL[1:0]: bits (RNGSEL Kernel Clock Source Selection)
    0=HSI48 (HSI48 clock used as RNG clock source); 1=HSI48_DIV2 (HSI48/2 clock used as RNG clock source); 2=HSI (HSI clock used as RNG clock source)
  [11] SAESSEL — SAES Kernel Clock Source Selection
    0=SHSI (SHSI clock used as SAES clock source); 1=DIV2 (SHSI_DIV2 clock used as SAES clock source)
  [10:8] SAI2SEL — SAI2SEL[2:0]: bits (SAI2 Kernel Clock Source Selection)
  [7:5] SAI1SEL — SAI1SEL[2:0]: bits (SAI1 Kernel Clock Source Selection)
  [2:0] MDF1SEL — MDF1SEL[2:0]: bits (MDF1 Kernel Clock Source Selection)
    0=HCLK (HCLK clock used as MDF1 clock); 1=PLL1 (PLL1 clock used as MDF1 clock); 2=PLL3 (PLL3 clock used as MDF1 clock); 4=MSIK (MSIK clock used as MDF1 clock); 3=PIN (PIN SAI1_EXTCLK clock used as MDF1 clock)
0xE8 CCIPR3 — IPs Clocks Configuration Register 3
  [18:16] ADF1SEL — ADF1SEL[2:0]: bits (ADF1 Kernel Clock Source Selection)
    0=HCLK (HCLK clock used as ADF1 clock); 1=PLL1 (PLL1 clock used as ADF1 clock); 2=PLL3 (PLL3 clock used as ADF1 clock); 4=MSIK (MSIK clock used as ADF1 clock); 3=PIN (PIN SAI1_EXTCLK clock used as ADF1 clock)
  [15] DAC1SEL — DAC1 Sample & Hold Clock Source Selection
    0=LSE (LSE clock used as DAC1 clock); 1=LSI (LSI clock used as DAC1 clock)
  [14:12] ADCDACSEL — ADCDACSEL[2:0]: bits (ADC1, ADC4 and DAC1 Kernel Clock Source Selection)
    0=HCLK (No clock used as ADCx/DAC1 clock source); 1=SYSCLK (SYSCLK clock used as ADCx/DAC1 clock source); 2=PLL2 (PLL2 clock used as ADCx/DAC1 clock source); 3=HSE (HSE clock used as ADCx/DAC1 clock source); 4=HSI (HSI clock used as ADCx/DAC1 clock source); 5=MSIK (MSIK clock used as ADCx/DAC1 clock source)
  [11:10] LPTIM1SEL — LPTIM1SEL[1:0]: bits (LPTIM1 Kernel Clock Source Selection)
  [9:8] LPTIM34SEL — LPTIM34SEL[1:0]: bits (LPTIM3 and LPTIM4 Kernel Clock Source Selection)
  [7:6] I2C3SEL — I2C3SEL[1:0]: bits (I2C3 Kernel Clock Source Selection)
  [4:3] SPI3SEL — SPI3SEL[1:0]: bits (SPI3 Kernel Clock Source Selection)
  [2:0] LPUART1SEL — LPUART1SEL[2:0]: bits (LPUART1 Kernel Clock Source Selection)
    0=PCLK3 (PCLK3 clock used as LPUART1 clock source); 1=SYSCLK (SYSCLK clock used as LPUART1 clock source); 2=HSI (HSI clock used as LPUART1 clock source); 3=LSE (LSE clock used as LPUART1 clock source); 4=MSIK (MSIK clock used as LPUART1 clock source)
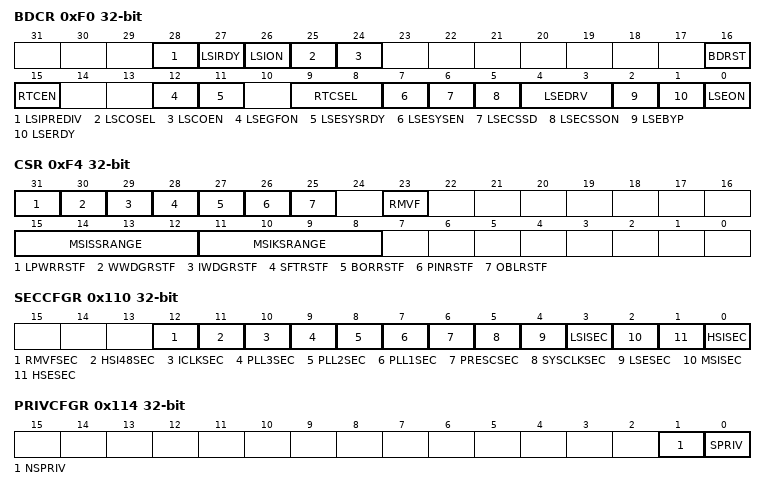
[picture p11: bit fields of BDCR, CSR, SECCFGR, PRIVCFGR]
0xF0 BDCR — Backup Domain Control Register
  [28] LSIPREDIV — Low-speed Clock Divider Configuration
    0=DIV_1 (LSI divided by 1); 1=DIV_128 (LSI divided by 128)
  [27] LSIRDY — LSI Oscillator Ready
  [26] LSION — LSI Oscillator Enable
  [25] LSCOSEL — Low-speed Clock Output Selection
    0=LSI (LSI selection for low speed clock); 1=LSE (LSE selection for low speed clock)
  [24] LSCOEN — Low-speed Clock Output (LSCO) Enable
  [16] BDRST — Backup Domain Software Reset
  [15] RTCEN — RTC Clock Enable
  [12] LSEGFON — LSE Clock Glitch Filter Enable
  [11] LSESYSRDY — LSE System Clock (LSESYS) Ready
  [9:8] RTCSEL — RTCSEL[1:0]: bits (RTC Clock Source Selection)
    0=NONE (No clock used as RTC clock); 1=LSE (LSE oscillator clock used as RTC clock); 2=LSI (LSI oscillator clock used as RTC clock); 3=HSE_DIV32 (HSE oscillator clock divided by 32 used as RTC clock)
  [7] LSESYSEN — LSE System Clock (LSESYS) Enable
  [6] LSECSSD — CSS on LSE failure Detection
  [5] LSECSSON — CSS on LSE Enable
  [4:3] LSEDRV — LSEDRV[1:0]: bits (LSE Oscillator Drive Capability)
    0=LOW (Xtal mode lower driving capability); 1=MEDIUMLOW (Xtal mode medium low driving capability); 2=MEDIUMHIGH (Xtal mode medium high driving capability); 3=HIGH (Xtal mode higher driving capability)
  [2] LSEBYP — LSE Oscillator Bypass
  [1] LSERDY — LSE Oscillator Ready
  [0] LSEON — LSE Oscillator Enable
0xF4 CSR — V33 Clock Control & Status Register
  [31] LPWRRSTF — Low-power Reset Flag
  [30] WWDGRSTF — Window Watchdog Reset Flag
  [29] IWDGRSTF — Independent Watchdog Reset Flag
  [28] SFTRSTF — Software Reset Flag
  [27] BORRSTF — BOR Flag
  [26] PINRSTF — NRST Pin Reset Flag
  [25] OBLRSTF — Option Byte Loader Reset Flag
  [23] RMVF — Remove Reset Flag
  [15:12] MSISSRANGE — MSISSRANGE[3:0]:bits (MSIS Range After Standby Mode)
    4=MSIS = 4 MHz; 5=MSIS = 2 MHz; 6=MSIS = 1.5 MHz; 7=MSIS = 1 MHz; 8=MSIS = 3.072 MHz
  [11:8] MSIKSRANGE — MSIKSRANGE[3:0]:bits (MSIK Range After Standby Mode)
    4=MSIK = 4 MHz; 5=MSIK = 2 MHz; 6=MSIK = 1.5 MHz; 7=MSIK = 1 MHz; 8=MSIK = 3.072 MHz
0x110 SECCFGR — RCC secure configuration register
  [12] RMVFSEC — Remove Reset Flag Security
  [11] HSI48SEC — HSI48 Clock Configuration and Status Bits Security
  [10] ICLKSEC — 48 MHz Clock Source Selection Security
  [9] PLL3SEC — PLL3 Clock Configuration and Status Bits Security
  [8] PLL2SEC — PLL2 Clock Configuration and Status Bits Security
  [7] PLL1SEC — PLL1 Clock Configuration and Status Bits Security
  [6] PRESCSEC — AHBx/APBx Prescaler Configuration Bits Security
  [5] SYSCLKSEC — SYSCLK Clock Selection, STOPWUCK bit, Clock Output on MCO Configuration Security
  [4] LSESEC — LSE Clock Configuration and Status Bits Security
  [3] LSISEC — LSI Clock Configuration and Status Bits Security
  [2] MSISEC — MSI Clock Configuration and Status Bits Security
  [1] HSESEC — HSE Clock Configuration Bits, Status Bits and HSE_CSS Security
  [0] HSISEC — HSI Clock Configuration and Status Bits Security
0x114 PRIVCFGR — RCC privilege configuration register
  [1] NSPRIV — RCC Non-Secure Functions Privilege Configuration
  [0] SPRIV — RCC Secure Functions Privilege Configuration
